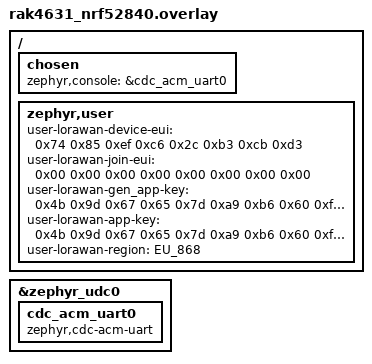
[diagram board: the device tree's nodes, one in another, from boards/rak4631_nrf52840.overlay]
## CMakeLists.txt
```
# SPDX-FileCopyrightText: Copyright (c) 2026 RAKwireless
# SPDX-License-Identifier: Apache-2.0

cmake_minimum_required(VERSION 3.20.0)

find_package(Zephyr REQUIRED HINTS $ENV{ZEPHYR_BASE})
project(rzi_lorawan_fuota)

target_sources(app PRIVATE src/main.c)
```

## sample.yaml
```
# SPDX-FileCopyrightText: Copyright (c) 2026 RAKwireless
# SPDX-License-Identifier: Apache-2.0

sample:
  name: RZI LoRaWAN FUOTA
  description: >
    Join a LoRaWAN network and accept ChirpStack FUOTA deployments through RZI
tests:
  sample.rzi.lorawan.fuota:
    sysbuild: true
    build_only: true
    tags:
      - rzi
      - lorawan
      - fuota
    platform_allow:
      - rak4631/nrf52840/rzi
      - rak3372_f/stm32wle5xx
    integration_platforms:
      - rak4631/nrf52840/rzi
      - rak3372_f/stm32wle5xx
```

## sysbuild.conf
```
# SPDX-FileCopyrightText: Copyright (c) 2026 RAKwireless
# SPDX-License-Identifier: Apache-2.0

SB_CONFIG_BOOTLOADER_MCUBOOT=y
SB_CONFIG_MCUBOOT_MODE_OVERWRITE_ONLY=y
SB_CONFIG_MERGED_HEX_FILES=y
```

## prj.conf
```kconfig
# SPDX-FileCopyrightText: Copyright (c) 2026 RAKwireless
# SPDX-License-Identifier: Apache-2.0

CONFIG_GPIO=y
CONFIG_SPI=y
CONFIG_SERIAL=y
CONFIG_FLASH=y
CONFIG_PM_DEVICE=y
CONFIG_TEST_RANDOM_GENERATOR=y

CONFIG_CONSOLE=y
CONFIG_UART_CONSOLE=y
CONFIG_UART_LINE_CTRL=y
CONFIG_USE_SEGGER_RTT=n
CONFIG_USB_DEVICE_STACK_NEXT=y
CONFIG_CDC_ACM_SERIAL_INITIALIZE_AT_BOOT=y
CONFIG_LOG_PROCESS_THREAD_STARTUP_DELAY_MS=4000
CONFIG_USBD_CDC_ACM_LOG_LEVEL_OFF=y
CONFIG_USBD_LOG_LEVEL_OFF=y

CONFIG_LOG=y
CONFIG_LOG_BACKEND_SHOW_COLOR=n
CONFIG_LOG_BUFFER_SIZE=4096
CONFIG_MAIN_STACK_SIZE=4096
CONFIG_HEAP_MEM_POOL_SIZE=8192

CONFIG_LORA=n
CONFIG_LORAWAN=n

CONFIG_RZI=y
CONFIG_RZI_LORAWAN=y
CONFIG_RZI_MCUBOOT=y
CONFIG_STREAM_FLASH=y
CONFIG_IMG_MANAGER=y
CONFIG_RZI_LORAWAN_FUOTA=y
CONFIG_RZI_LORAWAN_EVENT_QUEUE_SIZE=16
CONFIG_LORA_BASICS_MODEM_DRIVERS_EVENT_TRIGGER_NO_THREAD=y

# Match ChirpStack device-profile package versions (v1 by default).
CONFIG_LORA_BASICS_MODEM_FUOTA_V1=y
CONFIG_LORA_BASICS_MODEM_FUOTA_MAX_NB_OF_FRAGMENTS_CONFIG=y
CONFIG_LORA_BASICS_MODEM_FUOTA_MAX_NB_OF_FRAGMENTS=200
CONFIG_LORA_BASICS_MODEM_FUOTA_MAX_SIZE_OF_FRAGMENTS_CONFIG=y
CONFIG_LORA_BASICS_MODEM_FUOTA_MAX_SIZE_OF_FRAGMENTS=100
```

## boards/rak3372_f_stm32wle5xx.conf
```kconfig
# SPDX-FileCopyrightText: Copyright (c) 2026 RAKwireless
# SPDX-License-Identifier: Apache-2.0
# STM32WLE5 has no USB device controller. Console is lpuart1 (PA2/PA3).

CONFIG_USB_DEVICE_STACK_NEXT=n
CONFIG_CDC_ACM_SERIAL_INITIALIZE_AT_BOOT=n
CONFIG_UART_LINE_CTRL=n

# Keep the FUOTA image within slot0 regardless of module discovery order.
CONFIG_USP_LOG_LEVEL_OFF=y
CONFIG_LORA_BASICS_MODEM_LOG_LEVEL_OFF=y
CONFIG_LORA_BASICS_MODEM_DRIVERS_LOG_LEVEL_OFF=y
```

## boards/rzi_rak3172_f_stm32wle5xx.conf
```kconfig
# SPDX-FileCopyrightText: Copyright (c) 2026 RAKwireless
# SPDX-License-Identifier: Apache-2.0
# STM32WLE5 has no USB device controller. Console is usart1 (PB6/PB7).

CONFIG_USB_DEVICE_STACK_NEXT=n
CONFIG_CDC_ACM_SERIAL_INITIALIZE_AT_BOOT=n
CONFIG_UART_LINE_CTRL=n
```

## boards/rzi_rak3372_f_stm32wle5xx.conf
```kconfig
# SPDX-FileCopyrightText: Copyright (c) 2026 RAKwireless
# SPDX-License-Identifier: Apache-2.0
# STM32WLE5 has no USB device controller. Console is lpuart1 (PA2/PA3).

CONFIG_USB_DEVICE_STACK_NEXT=n
CONFIG_CDC_ACM_SERIAL_INITIALIZE_AT_BOOT=n
CONFIG_UART_LINE_CTRL=n
```

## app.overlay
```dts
/* SPDX-FileCopyrightText: Copyright (c) 2026 RAKwireless */
/* SPDX-License-Identifier: Apache-2.0 */
/*
 * Application credentials. The console choice lives in the board overlay.
 */

/ {
	zephyr,user {
		/* Same OTAA identity as app/ (ChirpStack device RZI_001). */
		user-lorawan-device-eui = <0x74 0x85 0xef 0xc6 0x2c 0xb3 0xcb 0xd3>;
		user-lorawan-join-eui = <0x00 0x00 0x00 0x00 0x00 0x00 0x00 0x00>;
		user-lorawan-gen_app-key = <0x4b 0x9d 0x67 0x65 0x7d 0xa9 0xb6 0x60
					    0xf4 0xd4 0xe3 0xdd 0xf2 0xbb 0x71 0x59>;
		user-lorawan-app-key = <0x4b 0x9d 0x67 0x65 0x7d 0xa9 0xb6 0x60
					0xf4 0xd4 0xe3 0xdd 0xf2 0xbb 0x71 0x59>;
	};
};
```

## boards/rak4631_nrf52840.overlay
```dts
/* SPDX-License-Identifier: Apache-2.0 */

#include "rak4631_usp_compat.dtsi"

/ {
	chosen {
		zephyr,console = &cdc_acm_uart0;
	};

	zephyr,user {
		/* Same OTAA identity as app/ (ChirpStack device RZI_001). */
		user-lorawan-device-eui = <0x74 0x85 0xef 0xc6 0x2c 0xb3 0xcb 0xd3>;
		user-lorawan-join-eui = <0x00 0x00 0x00 0x00 0x00 0x00 0x00 0x00>;
		/* GenAppKey must be non-zero for ChirpStack multicast; match AppKey. */
		user-lorawan-gen_app-key = <0x4b 0x9d 0x67 0x65 0x7d 0xa9 0xb6 0x60
					    0xf4 0xd4 0xe3 0xdd 0xf2 0xbb 0x71 0x59>;
		user-lorawan-app-key = <0x4b 0x9d 0x67 0x65 0x7d 0xa9 0xb6 0x60
					0xf4 0xd4 0xe3 0xdd 0xf2 0xbb 0x71 0x59>;
		user-lorawan-region = "EU_868";
	};
};

&zephyr_udc0 {
	cdc_acm_uart0: cdc_acm_uart0 {
		compatible = "zephyr,cdc-acm-uart";
	};
};
```

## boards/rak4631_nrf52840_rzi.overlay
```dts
/* SPDX-FileCopyrightText: Copyright (c) 2026 RAKwireless */
/* SPDX-License-Identifier: Apache-2.0 */
/*
 * A board overlay replaces app.overlay, so include it first.
 */

#include "../app.overlay"

/ {
	chosen {
		zephyr,console = &board_cdc_acm_uart;
	};
};
```

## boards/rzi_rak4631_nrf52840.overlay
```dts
/* SPDX-FileCopyrightText: Copyright (c) 2026 RAKwireless */
/* SPDX-License-Identifier: Apache-2.0 */
/*
 * A board overlay replaces app.overlay, so include it first.
 */

#include "../app.overlay"

/ {
	chosen {
		zephyr,console = &cdc_acm_uart0;
	};
};
```

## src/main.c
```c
/* SPDX-FileCopyrightText: Copyright (c) 2026 RAKwireless */
/* SPDX-License-Identifier: Apache-2.0 */

#include <errno.h>
#include <zephyr/devicetree.h>
#include <zephyr/kernel.h>
#include <zephyr/logging/log.h>
#include <rzi/lorawan/fuota.h>
#include <rzi/lorawan/lorawan.h>

static __maybe_unused void ignore_result(int result)
{
	ARG_UNUSED(result);
}

LOG_MODULE_REGISTER(rzi_fuota_sample, LOG_LEVEL_INF);

#define USER_NODE       DT_PATH(zephyr_user)
#define LORAWAN_REGION  RZI_LORAWAN_REGION_EU_868
#define RETRY_DELAY_S   5
#define RETRY_DELAY     K_SECONDS(RETRY_DELAY_S)
#define UPLINK_INTERVAL K_SECONDS(5)

static K_SEM_DEFINE(stack_ready, 0, 1);
static K_SEM_DEFINE(join_done, 0, 1);
static volatile bool joined;

static const char *tx_status_str(enum rzi_lorawan_tx_status status)
{
	switch (status) {
	case RZI_LORAWAN_EVENT_TXDONE_SENT:
		return "TXDONE_SENT";
	case RZI_LORAWAN_EVENT_TXDONE_CONFIRMED:
		return "TXDONE_CONFIRMED";
	case RZI_LORAWAN_EVENT_TXDONE_NOT_SENT:
		return "TXDONE_NOT_SENT";
	default:
		return "TXDONE_UNKNOWN";
	}
}

static void log_uplink_done(const struct rzi_lorawan_tx_result *tx)
{
	if (tx->error != 0) {
		LOG_WRN("%s: %s", tx_status_str(tx->status), rzi_err_str(tx->error));
		return;
	}
	LOG_INF("%s", tx_status_str(tx->status));
}

static const char *fuota_state_str(enum rzi_fuota_state state)
{
	switch (state) {
	case RZI_FUOTA_STATE_IDLE:
		return "idle";
	case RZI_FUOTA_STATE_READY:
		return "ready";
	case RZI_FUOTA_STATE_TRANSFERRING:
		return "transferring";
	case RZI_FUOTA_STATE_COMPLETE:
		return "complete";
	case RZI_FUOTA_STATE_FAILED:
		return "failed";
	case RZI_FUOTA_STATE_APPLYING:
		return "applying";
	default:
		return "unknown";
	}
}

static void on_event(const struct rzi_lorawan_event *event, void *user_data)
{
	ARG_UNUSED(user_data);
	switch (event->type) {
	case RZI_LORAWAN_EVENT_READY:
		k_sem_give(&stack_ready);
		break;
	case RZI_LORAWAN_EVENT_STATE_CHANGED:
		if (event->state == RZI_LORAWAN_STATE_READY) {
			k_sem_give(&stack_ready);
		}
		break;
	case RZI_LORAWAN_EVENT_JOINED:
		joined = true;
		k_sem_give(&join_done);
		break;
	case RZI_LORAWAN_EVENT_JOIN_FAILED:
		joined = false;
		k_sem_give(&join_done);
		break;
	case RZI_LORAWAN_EVENT_TXDONE:
		log_uplink_done(&event->tx);
		break;
	case RZI_LORAWAN_EVENT_DOWNDATA:
		LOG_INF("Downlink: port %u, %u bytes, RSSI %d dBm, SNR %d/4 dB",
			event->downlink.port, (unsigned int)event->downlink.size,
			event->downlink.rssi_dbm, event->downlink.snr_quarter_db);
		break;
	case RZI_LORAWAN_EVENT_ERROR:
		LOG_ERR("Error: %s", rzi_err_str(event->error));
		break;
	default:
		break;
	}
}

static void on_fuota_state(enum rzi_fuota_state state, void *user_data)
{
	ARG_UNUSED(user_data);
	LOG_INF("FUOTA %s", fuota_state_str(state));
}

static void on_fuota_session_started(void *user_data)
{
	ARG_UNUSED(user_data);
	LOG_INF("FUOTA transfer started");
}

static void on_fuota_complete(int status, void *user_data)
{
	ARG_UNUSED(user_data);
	if (status != 0) {
		LOG_ERR("FUOTA failed: %s", rzi_err_str(status));
		return;
	}
	LOG_INF("FUOTA finished");
}

static const struct rzi_lorawan_callbacks callbacks = {
	.on_event = on_event,
};

static const struct rzi_fuota_callbacks fuota_callbacks = {
	.state_changed = on_fuota_state,
	.session_started = on_fuota_session_started,
	.complete = on_fuota_complete,
};

static int request_join(void)
{
	int rc;

	joined = false;
	k_sem_reset(&join_done);
	rc = rzi_lorawan_join(1, 0, RZI_LORAWAN_JOIN_INTERVAL_DEFAULT, 0);
	if (rc != 0) {
		LOG_WRN("Join rejected: %s", rzi_err_str(rc));
		return rc;
	}
	LOG_INF("Joining");
	k_sem_take(&join_done, K_FOREVER);
	if (!joined) {
		LOG_WRN("Join failed, retrying in %d s", RETRY_DELAY_S);
		return -RZI_ERR_NOT_READY;
	}
	return 0;
}

int main(void)
{
	static const uint8_t dev_eui[] = DT_PROP(USER_NODE, user_lorawan_device_eui);
	static const uint8_t join_eui[] = DT_PROP(USER_NODE, user_lorawan_join_eui);
	static const uint8_t app_key[] = DT_PROP(USER_NODE, user_lorawan_app_key);
	static const uint8_t gen_app_key[] = DT_PROP(USER_NODE, user_lorawan_gen_app_key);
	static const uint8_t payload[] = "RZI FUOTA";
	int rc;

	LOG_INF("RZI LoRaWAN FUOTA sample");
	rc = rzi_fuota_register_callbacks(&fuota_callbacks);
	if (rc != 0) {
		LOG_ERR("FUOTA callback registration failed: %s", rzi_err_str(rc));
		return rc;
	}
	rc = rzi_lorawan_register_callbacks(&callbacks);
	if (rc != 0) {
		LOG_ERR("Callback registration failed: %s", rzi_err_str(rc));
		return rc;
	}
	rc = rzi_lorawan_set_dev_eui(dev_eui, sizeof(dev_eui));
	if (rc != 0) {
		LOG_ERR("Credentials failed: %s", rzi_err_str(rc));
		return rc;
	}
	rc = rzi_lorawan_set_app_eui(join_eui, sizeof(join_eui));
	if (rc != 0) {
		LOG_ERR("Credentials failed: %s", rzi_err_str(rc));
		return rc;
	}
	rc = rzi_lorawan_set_app_key(app_key, sizeof(app_key));
	if (rc != 0) {
		LOG_ERR("Credentials failed: %s", rzi_err_str(rc));
		return rc;
	}
	rc = rzi_lorawan_set_gen_app_key(gen_app_key, sizeof(gen_app_key));
	if (rc != 0) {
		LOG_ERR("Credentials failed: %s", rzi_err_str(rc));
		return rc;
	}
	rc = rzi_lorawan_set_activation(RZI_LORAWAN_ACTIVATION_OTAA);
	if (rc != 0) {
		LOG_ERR("Credentials failed: %s", rzi_err_str(rc));
		return rc;
	}
	rc = rzi_lorawan_init(LORAWAN_REGION);
	if (rc != 0) {
		LOG_ERR("LoRaWAN init failed: %s", rzi_err_str(rc));
		return rc;
	}

	k_sem_take(&stack_ready, K_FOREVER);

	while (request_join() != 0) {
		ignore_result(rzi_lorawan_leave());
		k_sleep(RETRY_DELAY);
	}
	LOG_INF("Joined");

	for (;;) {
		rc = rzi_lorawan_send(1, payload, sizeof(payload) - 1, RZI_LORAWAN_MSG_UNCONFIRMED);
		if (rc != 0 && rc != -RZI_ERR_BUSY) {
			LOG_WRN("Uplink rejected: %s", rzi_err_str(rc));
		}
		k_sleep(UPLINK_INTERVAL);
	}
}
```
